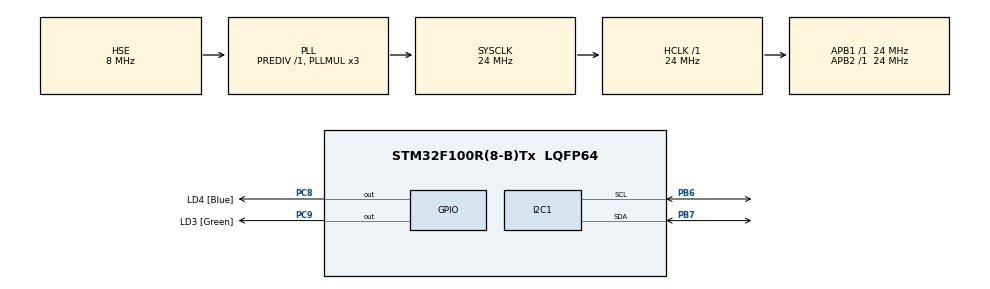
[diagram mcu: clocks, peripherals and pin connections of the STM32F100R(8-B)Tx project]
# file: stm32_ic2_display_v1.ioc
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Mcu.Family=STM32F1
PC15-OSC32_OUT.Mode=LSE-External-Oscillator
PD1-OSC_OUT.Mode=HSE-External-Oscillator
PC9.GPIO_Label=LD3 [Green]
PA14.GPIO_Label=TCK_SWCLK
PC8.Signal=GPIO_Output
PD0-OSC_IN.Signal=RCC_OSC_IN
PC14-OSC32_IN.Signal=RCC_OSC32_IN
RCC.SYSCLKSource=RCC_SYSCLKSOURCE_PLLCLK
ProjectManager.StackSize=0x400
PA0-WKUP.Signal=SYS_WKUP
RCC.PLLSource=RCC_PLLSOURCE_HSE
PD1-OSC_OUT.Signal=RCC_OSC_OUT
PC8.GPIO_Label=LD4 [Blue]
PA0-WKUP.Mode=SYS_WakeUp0
PA13.Signal=SYS_JTMS-SWDIO
ProjectManager.TargetToolchain=TrueSTUDIO
RCC.HCLKFreq_Value=24000000
RCC.APB2TimFreq_Value=24000000
PB6.Signal=I2C1_SCL
PB6.Mode=I2C
PC15-OSC32_OUT.Signal=RCC_OSC32_OUT
RCC.AHBFreq_Value=24000000
PD0-OSC_IN.Mode=HSE-External-Oscillator
board=STM32VLDISCOVERY
RCC.PLLMUL=RCC_PLL_MUL3
RCC.APB2Freq_Value=24000000
PC14-OSC32_IN.Mode=LSE-External-Oscillator
PA14.Mode=Serial_Wire
PB7.Signal=I2C1_SDA
PA13.Mode=Serial_Wire
Mcu.Name=STM32F100R(8-B)Tx
PA13.GPIO_Label=TMS_SWDIO
RCC.SYSCLKFreq_VALUE=24000000
Mcu.Package=LQFP64
PB7.Mode=I2C
PA14.Signal=SYS_JTCK-SWCLK
ProjectManager.HeapSize=0x200
NVIC.PriorityGroup=NVIC_PRIORITYGROUP_4
RCC.APB1TimFreq_Value=24000000
PC9.Signal=GPIO_Output
RCC.APB1Freq_Value=24000000

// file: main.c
/* USER CODE BEGIN Header */
/**
  ******************************************************************************
  * @file           : main.c
  * @brief          : Main program body
  ******************************************************************************
  * @attention
  *
  * <h2><center>&copy; Copyright (c) 2020 STMicroelectronics.
  * All rights reserved.</center></h2>
  *
  * This software component is licensed by ST under BSD 3-Clause license,
  * the "License"; You may not use this file except in compliance with the
  * License. You may obtain a copy of the License at:
  *                        opensource.org/licenses/BSD-3-Clause
  *
  ******************************************************************************
  */
/* USER CODE END Header */

#include "main.h"

/* USER CODE BEGIN Includes */
#include "stm32f1xx.h"

#include <stdio.h>
#include <stdlib.h>
#include <memory.h>
#include <stdbool.h>
#include <string.h>

#include "lib/controller/controller.h"
#include "lib/core/core.h"
#include "lib/logger/stdlogger.h"
/* USER CODE END Includes */

I2C_HandleTypeDef hi2c1;

void SystemClock_Config(void);
static void MX_GPIO_Init(void);
static void MX_I2C1_Init(void);

/* USER CODE BEGIN 0 */
void PrintfDataFromStruct(struct Node* node) // this is a temporary function
{
	int count = 0;
	while(node->Data[count] != NULL)
	{
	  printf(node->Data[count]);
	  ++count;
	}
	printf("\n");
}
/* USER CODE END 0 */

int main(void)
{

  /* MCU Configuration--------------------------------------------------------*/

  /* Reset of all peripherals, Initializes the Flash interface and the Systick. */
  HAL_Init();

  /* Configure the system clock */
  SystemClock_Config();

  /* Initialize all configured peripherals */
  MX_GPIO_Init();
  MX_I2C1_Init();
  /* USER CODE BEGIN 2 */
  TLogger* logger = NewStdLogger();
  TDisplay* display = NewI2cDisplay();
  TController* controller = NewController(logger, display);

  RunSomething(controller);

  free(logger);
  free(display);
  free(controller);

  /* USER CODE END 2 */

  /* Infinite loop */
  while (1)
  {

  }
}

void SystemClock_Config(void)
{
  RCC_OscInitTypeDef RCC_OscInitStruct = {0};
  RCC_ClkInitTypeDef RCC_ClkInitStruct = {0};

  /** Initializes the CPU, AHB and APB busses clocks
  */
  RCC_OscInitStruct.OscillatorType = RCC_OSCILLATORTYPE_HSE;
  RCC_OscInitStruct.HSEState = RCC_HSE_ON;
  RCC_OscInitStruct.HSEPredivValue = RCC_HSE_PREDIV_DIV1;
  RCC_OscInitStruct.PLL.PLLState = RCC_PLL_ON;
  RCC_OscInitStruct.PLL.PLLSource = RCC_PLLSOURCE_HSE;
  RCC_OscInitStruct.PLL.PLLMUL = RCC_PLL_MUL3;
  if (HAL_RCC_OscConfig(&RCC_OscInitStruct) != HAL_OK)
  {
    Error_Handler();
  }
  /** Initializes the CPU, AHB and APB busses clocks
  */
  RCC_ClkInitStruct.ClockType = RCC_CLOCKTYPE_HCLK|RCC_CLOCKTYPE_SYSCLK
                              |RCC_CLOCKTYPE_PCLK1|RCC_CLOCKTYPE_PCLK2;
  RCC_ClkInitStruct.SYSCLKSource = RCC_SYSCLKSOURCE_PLLCLK;
  RCC_ClkInitStruct.AHBCLKDivider = RCC_SYSCLK_DIV1;
  RCC_ClkInitStruct.APB1CLKDivider = RCC_HCLK_DIV1;
  RCC_ClkInitStruct.APB2CLKDivider = RCC_HCLK_DIV1;

  if (HAL_RCC_ClockConfig(&RCC_ClkInitStruct, FLASH_LATENCY_0) != HAL_OK)
  {
    Error_Handler();
  }
}

static void MX_I2C1_Init(void)
{

  hi2c1.Instance = I2C1;
  hi2c1.Init.ClockSpeed = 100000;
  hi2c1.Init.DutyCycle = I2C_DUTYCYCLE_2;
  hi2c1.Init.OwnAddress1 = 0;
  hi2c1.Init.AddressingMode = I2C_ADDRESSINGMODE_7BIT;
  hi2c1.Init.DualAddressMode = I2C_DUALADDRESS_DISABLE;
  hi2c1.Init.OwnAddress2 = 0;
  hi2c1.Init.GeneralCallMode = I2C_GENERALCALL_DISABLE;
  hi2c1.Init.NoStretchMode = I2C_NOSTRETCH_DISABLE;
  if (HAL_I2C_Init(&hi2c1) != HAL_OK)
  {
    Error_Handler();
  }

}

static void MX_GPIO_Init(void)
{
  GPIO_InitTypeDef GPIO_InitStruct = {0};

  /* GPIO Ports Clock Enable */
  __HAL_RCC_GPIOC_CLK_ENABLE();
  __HAL_RCC_GPIOD_CLK_ENABLE();
  __HAL_RCC_GPIOA_CLK_ENABLE();
  __HAL_RCC_GPIOB_CLK_ENABLE();

  /*Configure GPIO pin Output Level */
  HAL_GPIO_WritePin(GPIOC, LD4_Pin|LD3_Pin, GPIO_PIN_RESET);

  /*Configure GPIO pin : USER_BUTTON_Pin */
  GPIO_InitStruct.Pin = USER_BUTTON_Pin;
  GPIO_InitStruct.Mode = GPIO_MODE_INPUT;
  GPIO_InitStruct.Pull = GPIO_PULLDOWN;
  HAL_GPIO_Init(USER_BUTTON_GPIO_Port, &GPIO_InitStruct);

  /*Configure GPIO pins : LD4_Pin LD3_Pin */
  GPIO_InitStruct.Pin = LD4_Pin|LD3_Pin;
  GPIO_InitStruct.Mode = GPIO_MODE_OUTPUT_PP;
  GPIO_InitStruct.Pull = GPIO_NOPULL;
  GPIO_InitStruct.Speed = GPIO_SPEED_FREQ_LOW;
  HAL_GPIO_Init(GPIOC, &GPIO_InitStruct);

}

void Error_Handler(void)
{
}

/************************ (C) COPYRIGHT STMicroelectronics *****END OF FILE****/
